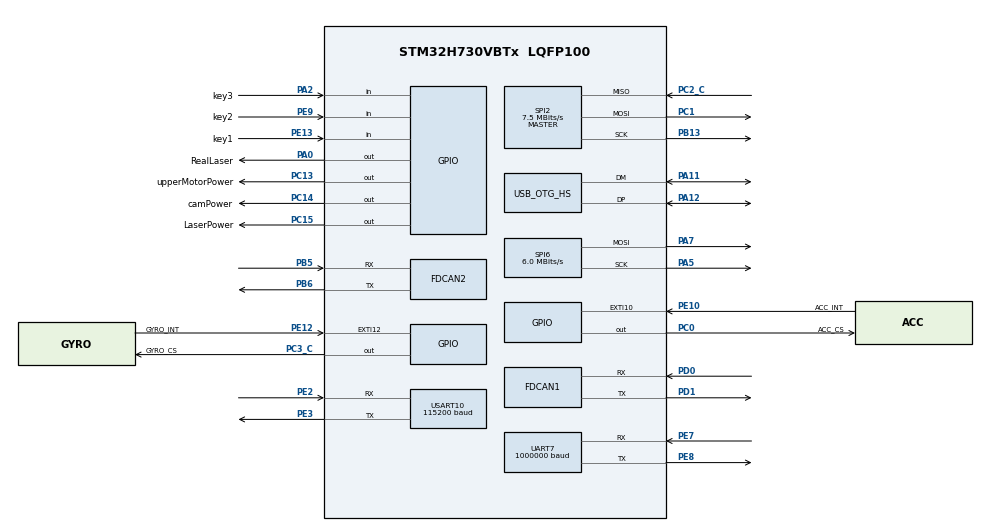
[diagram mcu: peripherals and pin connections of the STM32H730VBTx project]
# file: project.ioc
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Dma.Request0=SPI2_RX
Dma.Request1=SPI2_TX
Dma.SPI2_RX.0.Direction=DMA_PERIPH_TO_MEMORY
Dma.SPI2_RX.0.EventEnable=DISABLE
Dma.SPI2_RX.0.FIFOMode=DMA_FIFOMODE_DISABLE
Dma.SPI2_RX.0.Instance=DMA1_Stream0
Dma.SPI2_RX.0.MemDataAlignment=DMA_MDATAALIGN_BYTE
Dma.SPI2_RX.0.MemInc=DMA_MINC_ENABLE
Dma.SPI2_RX.0.Mode=DMA_NORMAL
Dma.SPI2_RX.0.PeriphDataAlignment=DMA_PDATAALIGN_BYTE
Dma.SPI2_RX.0.PeriphInc=DMA_PINC_DISABLE
Dma.SPI2_RX.0.Polarity=HAL_DMAMUX_REQ_GEN_RISING
Dma.SPI2_RX.0.Priority=DMA_PRIORITY_VERY_HIGH
Dma.SPI2_RX.0.RequestNumber=1
Dma.SPI2_RX.0.SignalID=NONE
Dma.SPI2_RX.0.SyncEnable=DISABLE
Dma.SPI2_RX.0.SyncPolarity=HAL_DMAMUX_SYNC_NO_EVENT
Dma.SPI2_RX.0.SyncRequestNumber=1
Dma.SPI2_RX.0.SyncSignalID=NONE
Dma.SPI2_TX.1.Direction=DMA_MEMORY_TO_PERIPH
Dma.SPI2_TX.1.EventEnable=DISABLE
Dma.SPI2_TX.1.FIFOMode=DMA_FIFOMODE_DISABLE
Dma.SPI2_TX.1.Instance=DMA1_Stream1
Dma.SPI2_TX.1.MemDataAlignment=DMA_MDATAALIGN_BYTE
Dma.SPI2_TX.1.MemInc=DMA_MINC_ENABLE
Dma.SPI2_TX.1.Mode=DMA_NORMAL
Dma.SPI2_TX.1.PeriphDataAlignment=DMA_PDATAALIGN_BYTE
Dma.SPI2_TX.1.PeriphInc=DMA_PINC_DISABLE
Dma.SPI2_TX.1.Polarity=HAL_DMAMUX_REQ_GEN_RISING
Dma.SPI2_TX.1.Priority=DMA_PRIORITY_HIGH
Dma.SPI2_TX.1.RequestNumber=1
Dma.SPI2_TX.1.SignalID=NONE
Dma.SPI2_TX.1.SyncEnable=DISABLE
Dma.SPI2_TX.1.SyncPolarity=HAL_DMAMUX_SYNC_NO_EVENT
Dma.SPI2_TX.1.SyncRequestNumber=1
Dma.SPI2_TX.1.SyncSignalID=NONE
FDCAN1.CalculateBaudRateNominal=1000000
FDCAN1.CalculateTimeBitNominal=1000
FDCAN1.CalculateTimeQuantumNominal=25.0
FDCAN1.DataSyncJumpWidth=10
FDCAN1.DataTimeSeg1=29
FDCAN1.DataTimeSeg2=10
FDCAN1.NominalPrescaler=1
FDCAN1.NominalSyncJumpWidth=10
FDCAN1.NominalTimeSeg1=29
FDCAN1.NominalTimeSeg2=10
FDCAN1.ProtocolException=ENABLE
FDCAN1.RxFifo0ElmtsNbr=32
FDCAN1.StdFiltersNbr=1
FDCAN1.TxFifoQueueElmtsNbr=8
FDCAN2.CalculateBaudRateNominal=1000000
FDCAN2.CalculateTimeBitNominal=1000
FDCAN2.CalculateTimeQuantumNominal=25.0
FDCAN2.DataSyncJumpWidth=10
FDCAN2.DataTimeSeg1=29
FDCAN2.DataTimeSeg2=10
FDCAN2.MessageRAMOffset=0x500
FDCAN2.NominalPrescaler=1
FDCAN2.NominalSyncJumpWidth=10
FDCAN2.NominalTimeSeg1=29
FDCAN2.NominalTimeSeg2=10
FDCAN2.ProtocolException=ENABLE
FDCAN2.RxFifo0ElmtsNbr=32
FDCAN2.RxFifo1ElmtsNbr=0
FDCAN2.StdFiltersNbr=1
FDCAN2.TxFifoQueueElmtsNbr=32
FREERTOS.INCLUDE_vTaskDelayUntil=1
FREERTOS.Tasks01=defaultTask,0,128,StartDefaultTask,Default,NULL,Dynamic,NULL,NULL
Mcu.Family=STM32H7
Mcu.Name=STM32H730VBTx
Mcu.Package=LQFP100
NVIC.DMA1_Stream0_IRQn=true\:5\:0\:false\:false\:true\:true\:false\:true\:true
NVIC.DMA1_Stream1_IRQn=true\:5\:0\:false\:false\:true\:true\:false\:true\:true
NVIC.FDCAN1_IT0_IRQn=true\:5\:0\:false\:false\:true\:true\:true\:true\:true
NVIC.FDCAN1_IT1_IRQn=true\:5\:0\:false\:false\:true\:true\:true\:true\:true
NVIC.FDCAN2_IT0_IRQn=true\:5\:0\:false\:false\:true\:true\:true\:true\:true
NVIC.FDCAN2_IT1_IRQn=true\:5\:0\:false\:false\:true\:true\:true\:true\:true
NVIC.OTG_HS_IRQn=true\:5\:0\:false\:false\:true\:true\:false\:true\:true
NVIC.PriorityGroup=NVIC_PRIORITYGROUP_4
NVIC.SPI2_IRQn=true\:5\:0\:false\:false\:true\:true\:false\:true\:true
NVIC.TIM23_IRQn=true\:15\:0\:false\:false\:true\:false\:false\:true\:true
NVIC.TimeBase=TIM23_IRQn
NVIC.TimeBaseIP=TIM23
NVIC.UART7_IRQn=true\:5\:0\:false\:false\:true\:true\:true\:true\:true
NVIC.USART10_IRQn=true\:5\:0\:false\:false\:true\:true\:true\:true\:true
PA0.GPIO_Label=RealLaser
PA0.Signal=GPIO_Output
PA11.Mode=Device_Only_FS
PA11.Signal=USB_OTG_HS_DM
PA12.Mode=Device_Only_FS
PA12.Signal=USB_OTG_HS_DP
PA13(JTMS/SWDIO).Mode=Serial_Wire
PA13(JTMS/SWDIO).Signal=DEBUG_JTMS-SWDIO
PA14(JTCK/SWCLK).Mode=Serial_Wire
PA14(JTCK/SWCLK).Signal=DEBUG_JTCK-SWCLK
PA2.GPIO_Label=key3
PA2.GPIO_PuPd=GPIO_PULLUP
PA2.Signal=GPIO_Input
PA5.Mode=TX_Only_Simplex_Unidirect_Master
PA5.Signal=SPI6_SCK
PA7.Mode=TX_Only_Simplex_Unidirect_Master
PA7.Signal=SPI6_MOSI
PB13.GPIO_Speed=GPIO_SPEED_FREQ_VERY_HIGH
PB13.Mode=Full_Duplex_Master
PB13.Signal=SPI2_SCK
PB5.Mode=FDCAN_Activate
PB5.Signal=FDCAN2_RX
PB6.Mode=FDCAN_Activate
PB6.Signal=FDCAN2_TX
PC0.GPIO_Label=ACC_CS
PC0.GPIO_Speed=GPIO_SPEED_FREQ_VERY_HIGH
PC0.PinState=GPIO_PIN_SET
PC0.Signal=GPIO_Output
PC1.GPIO_Speed=GPIO_SPEED_FREQ_VERY_HIGH
PC1.Mode=Full_Duplex_Master
PC1.Signal=SPI2_MOSI
PC13.GPIO_Label=upperMotorPower
PC13.Signal=GPIO_Output
PC14-OSC32_IN.GPIO_Label=camPower
PC14-OSC32_IN.Signal=GPIO_Output
PC15-OSC32_OUT.GPIO_Label=LaserPower
PC15-OSC32_OUT.Signal=GPIO_Output
PC2_C.GPIO_Speed=GPIO_SPEED_FREQ_VERY_HIGH
PC2_C.Mode=Full_Duplex_Master
PC2_C.Signal=SPI2_MISO
PC3_C.GPIO_Label=GYRO_CS
PC3_C.GPIO_Speed=GPIO_SPEED_FREQ_VERY_HIGH
PC3_C.PinState=GPIO_PIN_SET
PC3_C.Signal=GPIO_Output
PD0.Mode=FDCAN_Activate
PD0.Signal=FDCAN1_RX
PD1.Mode=FDCAN_Activate
PD1.Signal=FDCAN1_TX
PE10.GPIO_Label=ACC_INT
PE10.Signal=GPXTI10
PE12.GPIO_Label=GYRO_INT
PE12.Signal=GPXTI12
PE13.GPIO_Label=key1
PE13.GPIO_PuPd=GPIO_PULLUP
PE13.Signal=GPIO_Input
PE2.Mode=Asynchronous
PE2.Signal=USART10_RX
PE3.Mode=Asynchronous
PE3.Signal=USART10_TX
PE7.Mode=Asynchronous
PE7.Signal=UART7_RX
PE8.Mode=Asynchronous
PE8.Signal=UART7_TX
PE9.GPIO_Label=key2
PE9.GPIO_PuPd=GPIO_PULLUP
PE9.Signal=GPIO_Input
PH0-OSC_IN.Mode=HSE-External-Oscillator
PH0-OSC_IN.Signal=RCC_OSC_IN
PH1-OSC_OUT.Mode=HSE-External-Oscillator
PH1-OSC_OUT.Signal=RCC_OSC_OUT
ProjectManager.HeapSize=0x3000
ProjectManager.StackSize=0x1000
ProjectManager.TargetToolchain=MDK-ARM V5.32
RCC.ADCFreq_Value=80000000
RCC.APB1Freq_Value=137500000
RCC.APB2Freq_Value=137500000
RCC.APB3Freq_Value=137500000
RCC.APB4Freq_Value=137500000
RCC.CortexFreq_Value=550000000
RCC.D1PPRE=RCC_APB3_DIV2
RCC.D2PPRE1=RCC_APB1_DIV2
RCC.D2PPRE2=RCC_APB2_DIV2
RCC.D3PPRE=RCC_APB4_DIV2
RCC.DIVM1=3
RCC.DIVM2=3
RCC.DIVM3=6
RCC.DIVN1=68
RCC.DIVN2=40
RCC.DIVN3=120
RCC.DIVP1=1
RCC.DIVP2=4
RCC.DIVQ1=4
RCC.DIVQ2=8
RCC.DIVQ3=10
RCC.FDCANCLockSelection=RCC_FDCANCLKSOURCE_PLL2
RCC.HCLKFreq_Value=275000000
RCC.HPRE=RCC_HCLK_DIV2
RCC.HSE_VALUE=24000000
RCC.PLL2FRACN=0
RCC.PLL3FRACN=0
RCC.PLLFRACN=6144
RCC.PLLSourceVirtual=RCC_PLLSOURCE_HSE
RCC.SPI123CLockSelection=RCC_SPI123CLKSOURCE_PLL3
RCC.SPI6CLockSelection=RCC_SPI6CLKSOURCE_HSE
RCC.SYSCLKFreq_VALUE=550000000
RCC.SYSCLKSource=RCC_SYSCLKSOURCE_PLLCLK
RCC.USBCLockSelection=RCC_USBCLKSOURCE_PLL3
RCC.USBFreq_Value=48000000
SPI2.BaudRatePrescaler=SPI_BAUDRATEPRESCALER_32
SPI2.CLKPhase=SPI_PHASE_2EDGE
SPI2.CLKPolarity=SPI_POLARITY_HIGH
SPI2.CalculateBaudRate=7.5 MBits/s
SPI2.DataSize=SPI_DATASIZE_8BIT
SPI2.Direction=SPI_DIRECTION_2LINES
SPI2.Mode=SPI_MODE_MASTER
SPI2.VirtualType=VM_MASTER
SPI6.BaudRatePrescaler=SPI_BAUDRATEPRESCALER_4
SPI6.CLKPhase=SPI_PHASE_2EDGE
SPI6.CLKPolarity=SPI_POLARITY_LOW
SPI6.CalculateBaudRate=6.0 MBits/s
SPI6.DataSize=SPI_DATASIZE_8BIT
SPI6.Direction=SPI_DIRECTION_2LINES_TXONLY
SPI6.Mode=SPI_MODE_MASTER
SPI6.VirtualType=VM_MASTER
UART7.BaudRate=1000000
USART10.BaudRate=115200
USART10.VirtualMode=VM_ASYNC
USB_DEVICE.APP_RX_DATA_SIZE=512
USB_DEVICE.APP_TX_DATA_SIZE=512
USB_DEVICE.CLASS_NAME_HS=CDC
USB_DEVICE.VirtualMode=Cdc
USB_DEVICE.VirtualModeHS=Cdc_HS
USB_OTG_HS.VirtualMode-Device_Only_FS=Device_Only_FS
VP_FREERTOS_VS_CMSIS_V1.Mode=CMSIS_V1
VP_MEMORYMAP_VS_MEMORYMAP.Mode=CurAppReg
VP_SYS_VS_tim23.Mode=TIM23
VP_USB_DEVICE_VS_USB_DEVICE_CDC_HS.Mode=CDC_HS
board=custom

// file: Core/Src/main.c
/* USER CODE BEGIN Header */
/**
  ******************************************************************************
  * @file           : main.c
  * @brief          : Main program body
  ******************************************************************************
  * @attention
  *
  * Copyright (c) 2025 STMicroelectronics.
  * All rights reserved.
  *
  * This software is licensed under terms that can be found in the LICENSE file
  * in the root directory of this software component.
  * If no LICENSE file comes with this software, it is provided AS-IS.
  *
  ******************************************************************************
  */
/* USER CODE END Header */
#include "main.h"
#include "cmsis_os.h"
#include "dma.h"
#include "fdcan.h"
#include "spi.h"
#include "usart.h"
#include "usb_device.h"
#include "gpio.h"

/* USER CODE BEGIN Includes */
#include "system.h"
/* USER CODE END Includes */

void SystemClock_Config(void);
void PeriphCommonClock_Config(void);
void MX_FREERTOS_Init(void);

int main(void)
{

  /* MCU Configuration--------------------------------------------------------*/

  /* Reset of all peripherals, Initializes the Flash interface and the Systick. */
  HAL_Init();

  /* Configure the system clock */
  SystemClock_Config();

  /* Configure the peripherals common clocks */
  PeriphCommonClock_Config();

  /* Initialize all configured peripherals */
  MX_GPIO_Init();
  MX_DMA_Init();
  MX_FDCAN1_Init();
  MX_FDCAN2_Init();
  MX_SPI6_Init();
  MX_UART7_Init();
  MX_USART10_UART_Init();
  MX_SPI2_Init();
  /* USER CODE BEGIN 2 */
  hardwareInit();
  createTask();

  /* USER CODE END 2 */

  /* Call init function for freertos objects (in cmsis_os2.c) */
  MX_FREERTOS_Init();

  /* Start scheduler */
  osKernelStart();

  /* We should never get here as control is now taken by the scheduler */

  /* Infinite loop */
  while (1)
  {

  }
}

void SystemClock_Config(void)
{
  RCC_OscInitTypeDef RCC_OscInitStruct = {0};
  RCC_ClkInitTypeDef RCC_ClkInitStruct = {0};

  /** Supply configuration update enable
  */
  HAL_PWREx_ConfigSupply(PWR_LDO_SUPPLY);

  /** Configure the main internal regulator output voltage
  */
  __HAL_PWR_VOLTAGESCALING_CONFIG(PWR_REGULATOR_VOLTAGE_SCALE0);

  while(!__HAL_PWR_GET_FLAG(PWR_FLAG_VOSRDY)) {}

  /** Initializes the RCC Oscillators according to the specified parameters
  * in the RCC_OscInitTypeDef structure.
  */
  RCC_OscInitStruct.OscillatorType = RCC_OSCILLATORTYPE_HSE;
  RCC_OscInitStruct.HSEState = RCC_HSE_ON;
  RCC_OscInitStruct.PLL.PLLState = RCC_PLL_ON;
  RCC_OscInitStruct.PLL.PLLSource = RCC_PLLSOURCE_HSE;
  RCC_OscInitStruct.PLL.PLLM = 3;
  RCC_OscInitStruct.PLL.PLLN = 68;
  RCC_OscInitStruct.PLL.PLLP = 1;
  RCC_OscInitStruct.PLL.PLLQ = 4;
  RCC_OscInitStruct.PLL.PLLR = 2;
  RCC_OscInitStruct.PLL.PLLRGE = RCC_PLL1VCIRANGE_3;
  RCC_OscInitStruct.PLL.PLLVCOSEL = RCC_PLL1VCOWIDE;
  RCC_OscInitStruct.PLL.PLLFRACN = 6144;
  if (HAL_RCC_OscConfig(&RCC_OscInitStruct) != HAL_OK)
  {
    Error_Handler();
  }

  /** Initializes the CPU, AHB and APB buses clocks
  */
  RCC_ClkInitStruct.ClockType = RCC_CLOCKTYPE_HCLK|RCC_CLOCKTYPE_SYSCLK
                              |RCC_CLOCKTYPE_PCLK1|RCC_CLOCKTYPE_PCLK2
                              |RCC_CLOCKTYPE_D3PCLK1|RCC_CLOCKTYPE_D1PCLK1;
  RCC_ClkInitStruct.SYSCLKSource = RCC_SYSCLKSOURCE_PLLCLK;
  RCC_ClkInitStruct.SYSCLKDivider = RCC_SYSCLK_DIV1;
  RCC_ClkInitStruct.AHBCLKDivider = RCC_HCLK_DIV2;
  RCC_ClkInitStruct.APB3CLKDivider = RCC_APB3_DIV2;
  RCC_ClkInitStruct.APB1CLKDivider = RCC_APB1_DIV2;
  RCC_ClkInitStruct.APB2CLKDivider = RCC_APB2_DIV2;
  RCC_ClkInitStruct.APB4CLKDivider = RCC_APB4_DIV2;

  if (HAL_RCC_ClockConfig(&RCC_ClkInitStruct, FLASH_LATENCY_3) != HAL_OK)
  {
    Error_Handler();
  }
}

void PeriphCommonClock_Config(void)
{
  RCC_PeriphCLKInitTypeDef PeriphClkInitStruct = {0};

  /** Initializes the peripherals clock
  */
  PeriphClkInitStruct.PeriphClockSelection = RCC_PERIPHCLK_USB|RCC_PERIPHCLK_SPI2
                              |RCC_PERIPHCLK_FDCAN;
  PeriphClkInitStruct.PLL2.PLL2M = 3;
  PeriphClkInitStruct.PLL2.PLL2N = 40;
  PeriphClkInitStruct.PLL2.PLL2P = 4;
  PeriphClkInitStruct.PLL2.PLL2Q = 8;
  PeriphClkInitStruct.PLL2.PLL2R = 2;
  PeriphClkInitStruct.PLL2.PLL2RGE = RCC_PLL2VCIRANGE_3;
  PeriphClkInitStruct.PLL2.PLL2VCOSEL = RCC_PLL2VCOWIDE;
  PeriphClkInitStruct.PLL2.PLL2FRACN = 0;
  PeriphClkInitStruct.PLL3.PLL3M = 6;
  PeriphClkInitStruct.PLL3.PLL3N = 120;
  PeriphClkInitStruct.PLL3.PLL3P = 2;
  PeriphClkInitStruct.PLL3.PLL3Q = 10;
  PeriphClkInitStruct.PLL3.PLL3R = 2;
  PeriphClkInitStruct.PLL3.PLL3RGE = RCC_PLL3VCIRANGE_2;
  PeriphClkInitStruct.PLL3.PLL3VCOSEL = RCC_PLL3VCOWIDE;
  PeriphClkInitStruct.PLL3.PLL3FRACN = 0;
  PeriphClkInitStruct.Spi123ClockSelection = RCC_SPI123CLKSOURCE_PLL3;
  PeriphClkInitStruct.FdcanClockSelection = RCC_FDCANCLKSOURCE_PLL2;
  PeriphClkInitStruct.UsbClockSelection = RCC_USBCLKSOURCE_PLL3;
  if (HAL_RCCEx_PeriphCLKConfig(&PeriphClkInitStruct) != HAL_OK)
  {
    Error_Handler();
  }
}

void HAL_TIM_PeriodElapsedCallback(TIM_HandleTypeDef *htim)
{
  if (htim->Instance == TIM23)
  {
    HAL_IncTick();
  }
}

void Error_Handler(void)
{
  __disable_irq();
  while (1)
  {
  }
}
